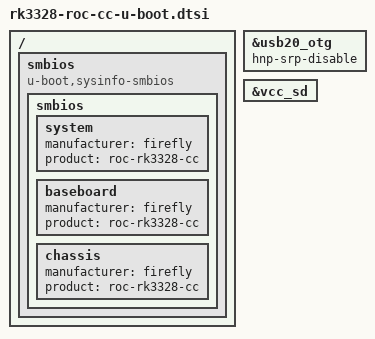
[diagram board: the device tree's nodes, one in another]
// SPDX-License-Identifier: GPL-2.0+
/*
 * (C) Copyright 2018-2019 Rockchip Electronics Co., Ltd
 */

#include "rk3328-u-boot.dtsi"
#include "rk3328-sdram-ddr4-1600.dtsi"

/ {
	smbios {
		compatible = "u-boot,sysinfo-smbios";

		smbios {
			system {
				manufacturer = "firefly";
				product = "roc-rk3328-cc";
			};

			baseboard {
				manufacturer = "firefly";
				product = "roc-rk3328-cc";
			};

			chassis {
				manufacturer = "firefly";
				product = "roc-rk3328-cc";
			};
		};
	};
};

&usb20_otg {
	hnp-srp-disable;
};

&vcc_sd {
	bootph-pre-ram;
};
